# TMS320F280049 register map
Vendor: Texas Instruments; Series: C2000 F28004x; File version: 0.2.0-generated
Registers are 16-bit, read-write, reset 0x0 unless marked. A register's access mark holds for its fields unless they carry their own. Offsets are from the block's base; [hi:lo] are bit positions; {n}, {i} and the like mark numbered series.

## ROMPREFETCHREGS — ROM PREFETCH Registers
Base 0x000BCC10
0x00 ROMPREFETCH 32-bit — ROM Prefetch Configuration Register
  [0] PFENABLE — ROM Prefetch Enable/Disable Control

## DCC0REGS — DCC Registers
Base 0x000BCE00
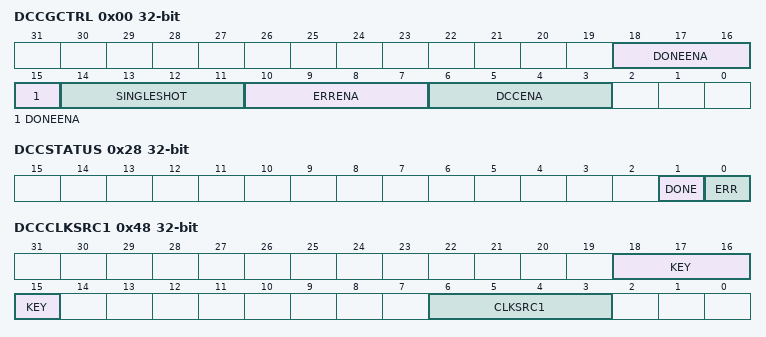
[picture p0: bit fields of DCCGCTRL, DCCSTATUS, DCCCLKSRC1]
0x00 DCCGCTRL 32-bit — Global Control Register
  [18:15] DONEENA — DONE Enable
  [14:11] SINGLESHOT — Single-Shot Enable
  [10:7] ERRENA — Error Enable
  [6:3] DCCENA — DCC Enable
0x08 DCCREV 32-bit — DCC Revision Register
  [12:10] MAJOR — Major Revision Number
  [10:5] MINOR — Minor Revision Number
0x10 DCCCNTSEED0 32-bit — Counter 0 Seed Value
  [31:19] COUNTSEED0 — Seed Value for Counter 0
0x18 DCCVALIDSEED0 32-bit — Valid 0 Seed Value
  [30:15] VALIDSEED — Seed Value for Valid Duration Counter 0
0x20 DCCCNTSEED1 32-bit — Counter 1 Seed Value
  [31:19] COUNTSEED1 — Seed Value for Counter 1
0x28 DCCSTATUS 32-bit
  [1] DONE — Single-Shot Done Flag
  [0] ERR — Error Flag
0x30 DCCCNT0 32-bit — Counter 0 Value
  [31:19] COUNT0 — Current Value of Counter 0
0x38 DCCVALID0 32-bit — Valid Value 0
  [30:15] VALID0 — Current Value of Valid 0
0x40 DCCCNT1 32-bit — Counter 1 Value
  [31:19] COUNT1 — Current Value of Counter 1
0x48 DCCCLKSRC1 32-bit — Clock Source 1
  [18:15] KEY — Enables or Disables Clock Source Selection for COUNT1
  [6:3] CLKSRC1 — Clock Source Select for Counter 1
0x50 DCCCLKSRC0 32-bit — Clock Source 0
  [6:3] CLKSRC0 — Clock Source Select for Counter 0

## ERADGLOBALREGS — ERAD GLOBAL Registers
Base 0x000BD000
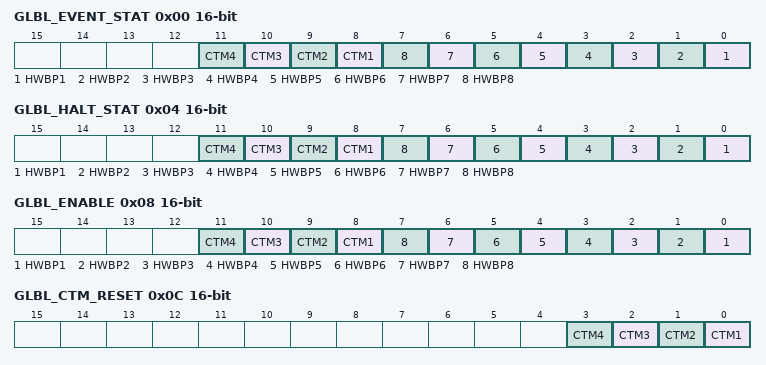
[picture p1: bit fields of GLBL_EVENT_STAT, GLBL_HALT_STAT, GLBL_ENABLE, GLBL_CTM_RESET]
0x00 GLBL_EVENT_STAT — Global Event Status Register
  [n+7] CTM{n} (n=1..4) — Counter Module Event Status
  [n-1] HWBP{n} (n=1..8) — Bus Comparator Module Event Status
0x04 GLBL_HALT_STAT — Global Halt Status Register
  [n+7] CTM{n} (n=1..4) — Counter Module Halt Status
  [n-1] HWBP{n} (n=1..8) — Bus Comparator Module Halt Status
0x08 GLBL_ENABLE — Global Enable Register
  [n+7] CTM{n} (n=1..4) — Counter Module Global Enable
  [n-1] HWBP{n} (n=1..8) — Bus Comparator Module Global Enable
0x0C GLBL_CTM_RESET — Global Counter Reset
  [n-1] CTM{n} (n=1..4) — Global Reset for the counters
0x14 GLBL_OWNER — Global Ownership
  [2:1] OWNER — Global Ownership Bits

## ERADHWBP1REGS — ERAD HWBP Registers
Base 0x000BD200
Same registers: ERADHWBP2REGS 0x000BD210, ERADHWBP3REGS 0x000BD220, ERADHWBP4REGS 0x000BD230, ERADHWBP5REGS 0x000BD240, ERADHWBP6REGS 0x000BD250, ERADHWBP7REGS 0x000BD260, ERADHWBP8REGS 0x000BD270
0x00 HWBP_MASK 32-bit — HWBP (EBC) Mask Register
  [31] MASK — Address mask register
0x04 HWBP_REF 32-bit — HWBP (EBC) Reference Register
  [31] REF — Address reference register
0x08 HWBP_CLEAR — HWBP (EBC) Clear Register
  [0] EVENT_CLR — Event Clear register
0x0C HWBP_CNTL — HWBP (EBC) Control Register
  [11:9] COMP_MODE — Compare mode
  [6] RTOSINT — RTOSINT bit
  [5] STOP — Stop bit (Halt/No Halt of CPU)
  [6:4] BUS_SEL — Bus select bits
0x0E HWBP_STATUS — HWBP (EBC) Status Register
  [15] STATUS — Status bits
  [15:13] MODULE_ID — Identification bits
  [0] EVENT_FIRED — HWBP (EBC) Event Fired bits

## ERADCOUNTER1REGS — ERAD COUNTER Registers
Base 0x000BD300
Same registers: ERADCOUNTER2REGS 0x000BD320, ERADCOUNTER3REGS 0x000BD340, ERADCOUNTER4REGS 0x000BD360
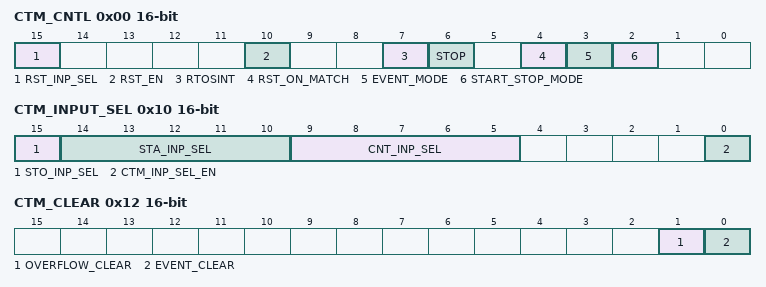
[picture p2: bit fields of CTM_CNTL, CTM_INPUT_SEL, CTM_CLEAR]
0x00 CTM_CNTL — Counter Control Register
  [15] RST_INP_SEL — Reset Input select
  [10] RST_EN — Enable Reset
  [7] RTOSINT — RTOSINT bit
  [6] STOP — Stop bit (Halt/No Halt of CPU)
  [4] RST_ON_MATCH — Reset_on_match bit
  [3] EVENT_MODE — Event mode bit
  [2] START_STOP_MODE — Start_stop mode bit
0x02 CTM_STATUS — Counter Status Register
  [15] STATUS — Status bits
  [15:11] MODULE_ID — Identification bits
  [1] OVERFLOW — Counter Overflowed
  [0] EVENT_FIRED — Counter Event Fired bits
0x04 CTM_REF 32-bit — Counter Reference Register
  [31] REF — The counter reference register
0x08 CTM_COUNT 32-bit — Counter Current Value Register
  [31] COUNT — The counter value register
0x0C CTM_MAX_COUNT 32-bit — Counter Max Count Value Register
  [31] MAX_COUNT — The maximum recorded counter value.
0x10 CTM_INPUT_SEL — Counter Input Select Register
  [15] STO_INP_SEL — Stop input select
  [14:10] STA_INP_SEL — Start input select
  [9:5] CNT_INP_SEL — Count input select
  [0] CTM_INP_SEL_EN — Count input select enable
0x12 CTM_CLEAR — Counter Clear Register
  [1] OVERFLOW_CLEAR — Clear OVERFLOW
  [0] EVENT_CLEAR — Clear EVENT_FIRED
